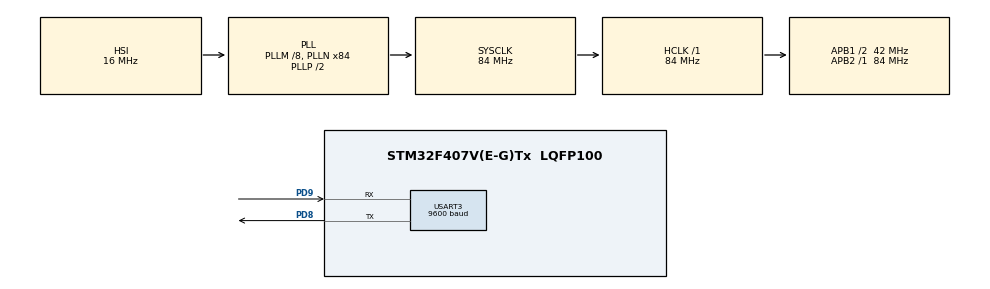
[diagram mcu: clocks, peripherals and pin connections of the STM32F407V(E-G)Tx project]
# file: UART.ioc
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Mcu.Family=STM32F4
Mcu.Name=STM32F407V(E-G)Tx
Mcu.Package=LQFP100
NVIC.PriorityGroup=NVIC_PRIORITYGROUP_4
NVIC.USART3_IRQn=true\:0\:0\:false\:false\:true\:true\:true
PD8.Mode=Asynchronous
PD8.Signal=USART3_TX
PD9.Mode=Asynchronous
PD9.Signal=USART3_RX
ProjectManager.HeapSize=0x200
ProjectManager.StackSize=0x400
ProjectManager.TargetToolchain=MDK-ARM V5
RCC.48MHZClocksFreq_Value=42000000
RCC.AHBFreq_Value=84000000
RCC.APB1CLKDivider=RCC_HCLK_DIV2
RCC.APB1Freq_Value=42000000
RCC.APB1TimFreq_Value=84000000
RCC.APB2Freq_Value=84000000
RCC.APB2TimFreq_Value=84000000
RCC.CortexFreq_Value=84000000
RCC.HCLKFreq_Value=84000000
RCC.HSE_VALUE=25000000
RCC.HSI_VALUE=16000000
RCC.LSE_VALUE=32768
RCC.PLLM=8
RCC.PLLN=84
RCC.SYSCLKFreq_VALUE=84000000
RCC.SYSCLKSource=RCC_SYSCLKSOURCE_PLLCLK
RCC.VCOOutputFreq_Value=168000000
USART3.BaudRate=9600
USART3.VirtualMode=VM_ASYNC
board=custom

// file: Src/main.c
/* USER CODE BEGIN Header */
/**
  ******************************************************************************
  * @file           : main.c
  * @brief          : Main program body
  ******************************************************************************
  * @attention
  *
  * <h2><center>&copy; Copyright (c) 2019 STMicroelectronics.
  * All rights reserved.</center></h2>
  *
  * This software component is licensed by ST under BSD 3-Clause license,
  * the "License"; You may not use this file except in compliance with the
  * License. You may obtain a copy of the License at:
  *                        opensource.org/licenses/BSD-3-Clause
  *
  ******************************************************************************
  */
/* USER CODE END Header */

#include "main.h"

/* USER CODE BEGIN Includes */
#include <stdio.h>
#include <string.h>
/* USER CODE END Includes */

/* USER CODE BEGIN PM */
uint16_t Value;
/* USER CODE END PM */

UART_HandleTypeDef huart3;

void SystemClock_Config(void);
static void MX_GPIO_Init(void);
static void MX_USART3_UART_Init(void);

/* USER CODE BEGIN 0 */
int fputc(int ch, FILE *f)
{
  return ITM_SendChar(ch);
}
/* USER CODE END 0 */

int main(void)
{

  /* MCU Configuration--------------------------------------------------------*/

  /* Reset of all peripherals, Initializes the Flash interface and the Systick. */
  HAL_Init();

  /* Configure the system clock */
  SystemClock_Config();

  /* Initialize all configured peripherals */
  MX_GPIO_Init();
  MX_USART3_UART_Init();

  /* Infinite loop */
  while (1)
  {

    /* USER CODE BEGIN 3 */
		char txt[] = "Hello";
    static char Buffer[20];
    HAL_UART_Transmit_IT(&huart3, txt, strlen(txt));
    HAL_UART_Receive_IT(&huart3, Buffer, 5);
    printf("Text: %s, %s\n", txt, Buffer);
  }
  /* USER CODE END 3 */
}

void SystemClock_Config(void)
{
  RCC_OscInitTypeDef RCC_OscInitStruct = {0};
  RCC_ClkInitTypeDef RCC_ClkInitStruct = {0};

  /** Configure the main internal regulator output voltage
  */
  __HAL_RCC_PWR_CLK_ENABLE();
  __HAL_PWR_VOLTAGESCALING_CONFIG(PWR_REGULATOR_VOLTAGE_SCALE1);
  /** Initializes the CPU, AHB and APB busses clocks
  */
  RCC_OscInitStruct.OscillatorType = RCC_OSCILLATORTYPE_HSI;
  RCC_OscInitStruct.HSIState = RCC_HSI_ON;
  RCC_OscInitStruct.HSICalibrationValue = RCC_HSICALIBRATION_DEFAULT;
  RCC_OscInitStruct.PLL.PLLState = RCC_PLL_ON;
  RCC_OscInitStruct.PLL.PLLSource = RCC_PLLSOURCE_HSI;
  RCC_OscInitStruct.PLL.PLLM = 8;
  RCC_OscInitStruct.PLL.PLLN = 84;
  RCC_OscInitStruct.PLL.PLLP = RCC_PLLP_DIV2;
  RCC_OscInitStruct.PLL.PLLQ = 4;
  if (HAL_RCC_OscConfig(&RCC_OscInitStruct) != HAL_OK)
  {
    Error_Handler();
  }
  /** Initializes the CPU, AHB and APB busses clocks
  */
  RCC_ClkInitStruct.ClockType = RCC_CLOCKTYPE_HCLK|RCC_CLOCKTYPE_SYSCLK
                              |RCC_CLOCKTYPE_PCLK1|RCC_CLOCKTYPE_PCLK2;
  RCC_ClkInitStruct.SYSCLKSource = RCC_SYSCLKSOURCE_PLLCLK;
  RCC_ClkInitStruct.AHBCLKDivider = RCC_SYSCLK_DIV1;
  RCC_ClkInitStruct.APB1CLKDivider = RCC_HCLK_DIV2;
  RCC_ClkInitStruct.APB2CLKDivider = RCC_HCLK_DIV1;

  if (HAL_RCC_ClockConfig(&RCC_ClkInitStruct, FLASH_LATENCY_2) != HAL_OK)
  {
    Error_Handler();
  }
}

static void MX_USART3_UART_Init(void)
{

  huart3.Instance = USART3;
  huart3.Init.BaudRate = 9600;
  huart3.Init.WordLength = UART_WORDLENGTH_8B;
  huart3.Init.StopBits = UART_STOPBITS_1;
  huart3.Init.Parity = UART_PARITY_NONE;
  huart3.Init.Mode = UART_MODE_TX_RX;
  huart3.Init.HwFlowCtl = UART_HWCONTROL_NONE;
  huart3.Init.OverSampling = UART_OVERSAMPLING_16;
  if (HAL_UART_Init(&huart3) != HAL_OK)
  {
    Error_Handler();
  }

}

static void MX_GPIO_Init(void)
{

  /* GPIO Ports Clock Enable */
  __HAL_RCC_GPIOD_CLK_ENABLE();

}

/* USER CODE BEGIN 4 */
void HAL_USART_RxCpltCallback(UART_HandleTypeDef *huart)
{
}
/* USER CODE END 4 */

void Error_Handler(void)
{
}

/************************ (C) COPYRIGHT STMicroelectronics *****END OF FILE****/
